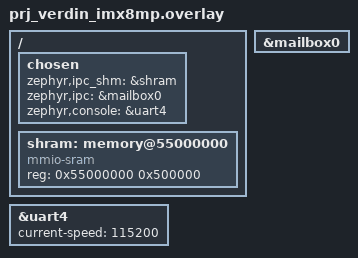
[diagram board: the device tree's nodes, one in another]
/*
This overlay is based on:
hmp_mcuxpresso-zephyr/sources/rpmsg-lite/zephyr/samples/rpmsglite_pingpong/remote/boards/mimxrt1160_evk_mimxrt1166_cm4.overlay
hmp_mcuxpresso-zephyr/zephyr/samples/subsys/ipc/openamp_rsc_table/boards/imx8mp_evk_mimx8ml8_m7.overlay
*/

/ {
    chosen {
        zephyr,ipc_shm = &shram;
        zephyr,ipc = &mailbox0;
		zephyr,console = &uart4;
    };

    shram: memory@55000000 {
        compatible = "mmio-sram";
        reg = <0x55000000 0x500000>;
    };
};

&mailbox0 {
    status = "okay";
};

&uart4 {
	status = "okay";
	current-speed = <115200>;
};
